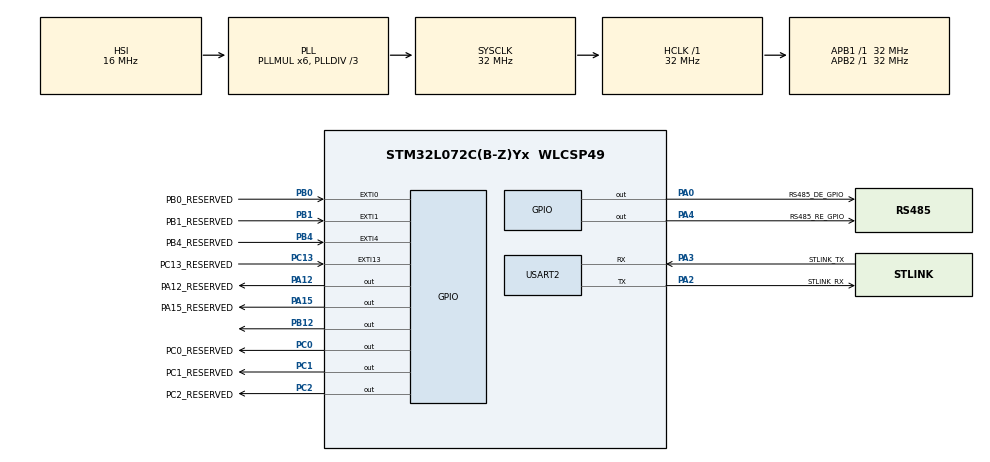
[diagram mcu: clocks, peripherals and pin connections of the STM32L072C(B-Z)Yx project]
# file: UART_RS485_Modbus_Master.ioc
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Mcu.Family=STM32L0
Mcu.Name=STM32L072C(B-Z)Yx
Mcu.Package=WLCSP49
NVIC.EXTI0_1_IRQn=true\:0\:0\:false\:false\:true\:true\:true
NVIC.EXTI4_15_IRQn=true\:0\:0\:false\:false\:true\:true\:true
NVIC.RTC_IRQn=true\:0\:0\:false\:false\:true\:true\:true
NVIC.USART2_IRQn=true\:0\:0\:false\:false\:true\:true\:true
PA0.GPIO_Label=RS485_DE_GPIO
PA0.GPIO_Speed=GPIO_SPEED_FREQ_HIGH
PA0.Signal=GPIO_Output
PA12.GPIO_Label=PA12_RESERVED
PA12.GPIO_Speed=GPIO_SPEED_FREQ_HIGH
PA12.Signal=GPIO_Output
PA15.GPIO_Label=PA15_RESERVED
PA15.GPIO_Speed=GPIO_SPEED_FREQ_HIGH
PA15.Signal=GPIO_Output
PA2.GPIO_Label=STLINK_RX
PA2.Mode=Asynchronous
PA2.Signal=USART2_TX
PA3.GPIO_Label=STLINK_TX
PA3.Mode=Asynchronous
PA3.Signal=USART2_RX
PA4.GPIO_Label=RS485_RE_GPIO
PA4.GPIO_Speed=GPIO_SPEED_FREQ_HIGH
PA4.Signal=GPIO_Output
PA6.GPIO_Label=PA6_RESERVED
PA6.Signal=SPI1_MISO
PA7.GPIO_Label=PA7_RESERVED
PA7.Signal=SPI1_MOSI
PB0.GPIO_Label=PB0_RESERVED
PB0.Signal=GPXTI0
PB1.GPIO_Label=PB1_RESERVED
PB1.Signal=GPXTI1
PB12.Signal=GPIO_Output
PB3.GPIO_Label=PB3_RESERVED
PB3.Signal=SPI1_SCK
PB4.GPIO_Label=PB4_RESERVED
PB4.Signal=GPXTI4
PC0.GPIO_Label=PC0_RESERVED
PC0.GPIO_Speed=GPIO_SPEED_FREQ_HIGH
PC0.Signal=GPIO_Output
PC1.GPIO_Label=PC1_RESERVED
PC1.GPIO_Speed=GPIO_SPEED_FREQ_HIGH
PC1.Signal=GPIO_Output
PC13.GPIO_Label=PC13_RESERVED
PC13.Signal=GPXTI13
PC2.GPIO_Label=PC2_RESERVED
PC2.GPIO_Speed=GPIO_SPEED_FREQ_HIGH
PC2.Signal=GPIO_Output
PH0-OSC_IN.Signal=RCC_OSC_IN
PH1-OSC_OUT.Signal=RCC_OSC_OUT
ProjectManager.HeapSize=0x200
ProjectManager.StackSize=0x400
ProjectManager.TargetToolchain=STM32CubeIDE
RCC.AHBFreq_Value=32000000
RCC.APB1Freq_Value=32000000
RCC.APB1TimFreq_Value=32000000
RCC.APB2Freq_Value=32000000
RCC.APB2TimFreq_Value=32000000
RCC.HCLKFreq_Value=32000000
RCC.HSE_VALUE=8000000
RCC.HSI16_VALUE=16000000
RCC.HSI48_VALUE=48000000
RCC.HSI_VALUE=16000000
RCC.LSE_VALUE=32768
RCC.MSI_VALUE=2097000
RCC.PLLDIV=RCC_PLLDIV_3
RCC.PLLMUL=RCC_PLLMUL_6
RCC.SYSCLKFreq_VALUE=32000000
RCC.SYSCLKSource=RCC_SYSCLKSOURCE_PLLCLK
RCC.VCOOutputFreq_Value=96000000
RTC.Alarm-Alarm\ A=RTC_ALARM_A
RTC.AlarmSubSecondMask-Alarm\ A=RTC_ALARMSUBSECONDMASK_NONE
RTC.AsynchPrediv=31
RTC.Format=RTC_FORMAT_BIN
RTC.SynchPrediv=1023
USART2.VirtualMode-Asynchronous=VM_ASYNC
VP_RTC_VS_RTC_Activate.Mode=RTC_Enabled
VP_RTC_VS_RTC_Alarm_A_Intern.Mode=Alarm A
VP_RTC_VS_RTC_Calendar.Mode=RTC_Calendar
VP_TIM7_VS_ClockSourceINT.Mode=Enable_Timer
board=B-L072Z-LRWAN1

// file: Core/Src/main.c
/* USER CODE BEGIN Header */
/**
  ******************************************************************************
  * @file           : main.c
  * @brief          : Main program body
  ******************************************************************************
  * @attention
  *
  * Copyright (c) 2022 STMicroelectronics.
  * All rights reserved.
  *
  * This software is licensed under terms that can be found in the LICENSE file
  * in the root directory of this software component.
  * If no LICENSE file comes with this software, it is provided AS-IS.
  *
  ******************************************************************************
  */
/* USER CODE END Header */
#include "main.h"
#include "rtc.h"
#include "tim.h"
#include "usart.h"
#include "gpio.h"
#include "mmodbus.h"

/* USER CODE BEGIN PV */
uint8_t uart_rx;
uint8_t data;
uint8_t rx_done = 0;
/* USER CODE END PV */

void SystemClock_Config(void);

int main(void)
{

  /* MCU Configuration--------------------------------------------------------*/

  /* Reset of all peripherals, Initializes the Flash interface and the Systick. */
  HAL_Init();

  /* Configure the system clock */
  SystemClock_Config();

  /* Initialize all configured peripherals */
  MX_GPIO_Init();
  MX_RTC_Init();
  MX_USART2_UART_Init();
  MX_TIM7_Init();
  /* USER CODE BEGIN 2 */
  HAL_UART_Receive_IT(&huart2, &uart_rx, 1);

  mmodbus_init(2500);
  mmodbus_writeCoil(1, 1, 2);

  /* USER CODE END 2 */

  /* Infinite loop */
  while (1)
  {
	  mmodbus_writeCoil(1, 1, 5);
	  HAL_Delay(100);
	  mmodbus_writeCoil(1, 2, 6);
	  HAL_Delay(100);
	  mmodbus_writeCoil(1, 3, 7);
	  HAL_Delay(100);
	  mmodbus_writeCoil(1, 4, 8);
	  HAL_Delay(100);
    /* USER CODE BEGIN 3 */
//	if (rx_done == 1)
//	{
//		rx_done = 0;
//		//HAL_GPIO_WritePin(GPIOB, GPIO_PIN_13 | GPIO_PIN_14, GPIO_PIN_SET);
//		HAL_Delay(100);
//		HAL_UART_Transmit(&huart2, &data, 1, 200);
//		data += 1;
//		HAL_UART_Transmit(&huart2, &data, 1, 200);
//		//HAL_UART_Transmit(&huart1, &uart_rx, 1, 200);
//		HAL_Delay(100);
//		//HAL_GPIO_WritePin(GPIOB, GPIO_PIN_13 | GPIO_PIN_14, GPIO_PIN_RESET);
//		HAL_UART_Receive_IT(&huart2, &uart_rx, 1);
//	}
  }
  /* USER CODE END 3 */
}

void SystemClock_Config(void)
{
  RCC_OscInitTypeDef RCC_OscInitStruct = {0};
  RCC_ClkInitTypeDef RCC_ClkInitStruct = {0};
  RCC_PeriphCLKInitTypeDef PeriphClkInit = {0};

  /** Configure the main internal regulator output voltage
  */
  __HAL_PWR_VOLTAGESCALING_CONFIG(PWR_REGULATOR_VOLTAGE_SCALE1);
  /** Initializes the RCC Oscillators according to the specified parameters
  * in the RCC_OscInitTypeDef structure.
  */
  RCC_OscInitStruct.OscillatorType = RCC_OSCILLATORTYPE_HSI|RCC_OSCILLATORTYPE_LSI;
  RCC_OscInitStruct.HSIState = RCC_HSI_ON;
  RCC_OscInitStruct.HSICalibrationValue = RCC_HSICALIBRATION_DEFAULT;
  RCC_OscInitStruct.LSIState = RCC_LSI_ON;
  RCC_OscInitStruct.PLL.PLLState = RCC_PLL_ON;
  RCC_OscInitStruct.PLL.PLLSource = RCC_PLLSOURCE_HSI;
  RCC_OscInitStruct.PLL.PLLMUL = RCC_PLLMUL_6;
  RCC_OscInitStruct.PLL.PLLDIV = RCC_PLLDIV_3;
  if (HAL_RCC_OscConfig(&RCC_OscInitStruct) != HAL_OK)
  {
    Error_Handler();
  }
  /** Initializes the CPU, AHB and APB buses clocks
  */
  RCC_ClkInitStruct.ClockType = RCC_CLOCKTYPE_HCLK|RCC_CLOCKTYPE_SYSCLK
                              |RCC_CLOCKTYPE_PCLK1|RCC_CLOCKTYPE_PCLK2;
  RCC_ClkInitStruct.SYSCLKSource = RCC_SYSCLKSOURCE_PLLCLK;
  RCC_ClkInitStruct.AHBCLKDivider = RCC_SYSCLK_DIV1;
  RCC_ClkInitStruct.APB1CLKDivider = RCC_HCLK_DIV1;
  RCC_ClkInitStruct.APB2CLKDivider = RCC_HCLK_DIV1;

  if (HAL_RCC_ClockConfig(&RCC_ClkInitStruct, FLASH_LATENCY_1) != HAL_OK)
  {
    Error_Handler();
  }
  PeriphClkInit.PeriphClockSelection = RCC_PERIPHCLK_USART2|RCC_PERIPHCLK_RTC;
  PeriphClkInit.Usart2ClockSelection = RCC_USART2CLKSOURCE_PCLK1;
  PeriphClkInit.RTCClockSelection = RCC_RTCCLKSOURCE_LSI;
  if (HAL_RCCEx_PeriphCLKConfig(&PeriphClkInit) != HAL_OK)
  {
    Error_Handler();
  }
}

/* USER CODE BEGIN 4 */

void HAL_UART_RxCpltCallback(UART_HandleTypeDef *huart)
{
	data = uart_rx;
	rx_done = 1;
	mmodbus_callback(data);
}

/* USER CODE END 4 */

void Error_Handler(void)
{
  __disable_irq();
  while (1)
  {
  }
}
